# ESP32-S31 register map
Vendor: ESPRESSIF SYSTEMS (SHANGHAI) CO., LTD.; Series: ESP32 S-Series; File version: 1
CPU: RV32IMAFC r0p0, little endian, no MPU, FPU, 0 interrupt priority bits
Address unit: 32 bits
Registers are 32-bit, read-write, reset 0x0 unless marked. A register's access mark holds for its fields unless they carry their own. Offsets are from the block's base; [hi:lo] are bit positions; {n}, {i} and the like mark numbered series.

## MEM_MONITOR0 — MEM_MONITOR0 Peripheral
Base 0x2D003000
Same registers: MEM_MONITOR1 0x2D004000
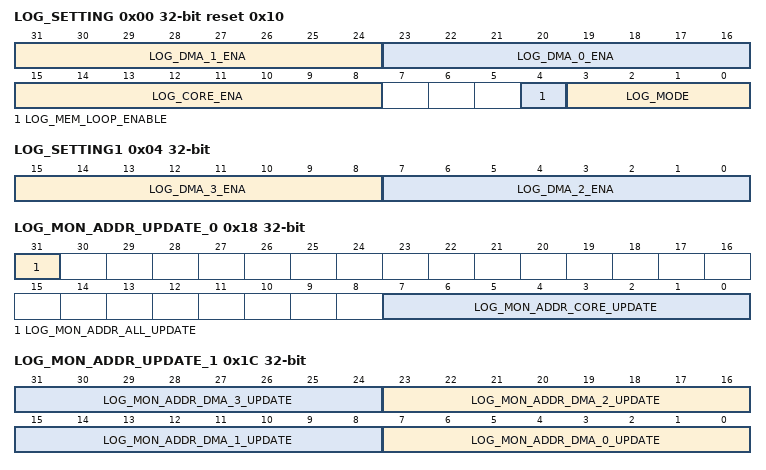
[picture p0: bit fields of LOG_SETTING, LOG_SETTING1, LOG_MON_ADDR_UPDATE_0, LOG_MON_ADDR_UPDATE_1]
0x00 LOG_SETTING reset 0x10 — Bus access logging configuration register
  [31:24] LOG_DMA_1_ENA — Configures whether to enable DMA_1 bus access logging.bit[0]: Configures whether to enable DMA_1 bus access logging. \\ 0: Disable \\ 1: Enable\\ Bit[7:1]: Reserved
  [23:16] LOG_DMA_0_ENA — Configures whether to enable DMA_0 bus access logging.bit[0]: Configures whether to enable DMA_0 bus access logging. \\ 0: Disable \\ 1: Enable\\ Bit[7:1]: Reserved
  [15:8] LOG_CORE_ENA — Configures whether to enable CPU bus access logging.bit[0]: Configures whether to enable HP CPU bus access logging. \\ 0: Disable \\ 1: Enable\\ Bit[7:1]: Reserved
  [4] LOG_MEM_LOOP_ENABLE — Configures the writing mode for recorded data.1: Loop mode\\ 0: Non-loop mode\\
  [3:0] LOG_MODE — Configures monitoring modes.bit[0]: Configures write monitoring. \\ 0: Disable \\ 1: Enable\\ bit[1]: Configures word monitoring. \\ 0: Disable \\ 1: Enable\\ bit[2]: Configures halfword monitoring. \\ 0: Disable \\ 1: Enable\\ bit[3]: Configures byte monitoring. \\ 0: Disable \\ 1: Enable\\
0x04 LOG_SETTING1 — Bus access logging configuration register
  [15:8] LOG_DMA_3_ENA — Configures whether to enable DMA_3 bus access logging.bit[0]: Configures whether to enable DMA_3 bus access logging. \\ 0: Disable \\ 1: Enable\\ Bit[7:1]: Reserved
  [7:0] LOG_DMA_2_ENA — Configures whether to enable DMA_2 bus access logging.bit[0]: Configures whether to enable DMA_2 bus access logging. \\ 0: Disable \\ 1: Enable\\ Bit[7:1]: Reserved
0x08 LOG_CHECK_DATA — Configures monitored data in Bus access logging
  [31:0] LOG_CHECK_DATA — Configures the data to be monitored during bus accessing.
0x0C LOG_DATA_MASK — Configures masked data in Bus access logging
  [3:0] LOG_DATA_MASK — Configures which byte(s) in MEM_MONITOR_LOG_CHECK_DATA_REG to mask.bit[0]: Configures whether to mask the least significant byte of MEM_MONITOR_LOG_CHECK_DATA_REG.\\ 0: Not mask \\ 1: Mask\\ bit[1]: Configures whether to mask the second least significant byte of MEM_MONITOR_LOG_CHECK_DATA_REG. \\ 0: Not mask \\ 1: Mask\\ bit[2]: Configures whether to mask the second most significant byte of MEM_MONITOR_LOG_CHECK_DATA_REG. \\ 0: Not mask \\ 1: Mask\\ bit[3]: Configures whether to mask the most significant byte of MEM_MONITOR_LOG_CHECK_DATA_REG. \\ 0: Not mask \\ 1: Mask\\
0x10 LOG_MIN — Configures monitored address space in Bus access logging
  [31:0] LOG_MIN — Configures the lower bound address of the monitored address space.
0x14 LOG_MAX — Configures monitored address space in Bus access logging
  [31:0] LOG_MAX — Configures the upper bound address of the monitored address space.
0x18 LOG_MON_ADDR_UPDATE_0 wo — Configures the address space of from MEM_MONITOR_LOG_MIN_REG to MEM_MONITOR_LOG_MAX_REG as the monitored address space of the certain master.
  [31] LOG_MON_ADDR_ALL_UPDATE — Configures the address space of from MEM_MONITOR_LOG_MIN_REG to MEM_MONITOR_LOG_MAX_REG as the monitored address space of all masters.1: Update\\ 0: Not update\\
  [7:0] LOG_MON_ADDR_CORE_UPDATE — Configures the monitored address space of the certain master. Bit[0]: Configures the address space of from MEM_MONITOR_LOG_MIN_REG to MEM_MONITOR_LOG_MAX_REG as the monitored address space of the HP CPU bus.1: Update\\ 0: Not update\\ Bit[7:1]: Reserved\\
0x1C LOG_MON_ADDR_UPDATE_1 wo — Configures the address space of from MEM_MONITOR_LOG_MIN_REG to MEM_MONITOR_LOG_MAX_REG as the monitored address space of the certain master.
  [8n+7:8n] LOG_MON_ADDR_DMA_{n}_UPDATE (n=0..3) — Configures the monitored address space of the certain master. Bit[0]: Configures the address space of from MEM_MONITOR_LOG_MIN_REG to MEM_MONITOR_LOG_MAX_REG as the monitored address space of the DMA_{n} bus.1: Update\\ 0: Not update\\ Bit[7:1]: Reserved\\
0x20 LOG_MEM_START — Configures the starting address of the storage memory for recorded data
  [31:0] LOG_MEM_START — Configures the starting address of the storage space for recorded data.
0x24 LOG_MEM_END — Configures the end address of the storage memory for recorded data
  [31:0] LOG_MEM_END — Configures the ending address of the storage space for recorded data.
0x28 LOG_MEM_CURRENT_ADDR ro — Represents the address for the next write
  [31:0] LOG_MEM_CURRENT_ADDR — Represents the address of the next write.
0x2C LOG_MEM_ADDR_UPDATE wo — Updates the address for the next write with the starting address for the recorded data
  [0] LOG_MEM_ADDR_UPDATE — Configures whether to update the value in MEM_MONITOR_LOG_MEM_START_REG to MEM_MONITOR_LOG_MEM_CURRENT_ADDR_REG. aggedright1: Update \\ 0: Not update (default) \\
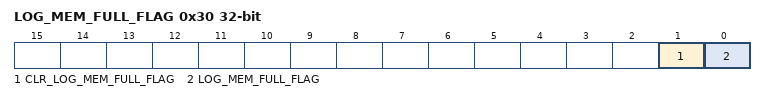
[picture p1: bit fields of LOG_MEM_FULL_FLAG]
0x30 LOG_MEM_FULL_FLAG access per field — Logging overflow status register
  [1] CLR_LOG_MEM_FULL_FLAG wo — Configures whether to clear the MEM_MONITOR_LOG_MEM_FULL_FLAG flag bit.0: Not clear\\ 1: Clear\\
  [0] LOG_MEM_FULL_FLAG ro — Represents whether data overflows the storage space.0: Not Overflow\\ 1: Overflow\\
0x34 CLOCK_GATE — Register clock control
  [0] CLK_EN — Configures whether to enable the register clock gating.0: Disable\\ 1: Enable\\
0x3FC DATE reset 0x2308140 — Version control register
  [27:0] DATE — Version control register.
